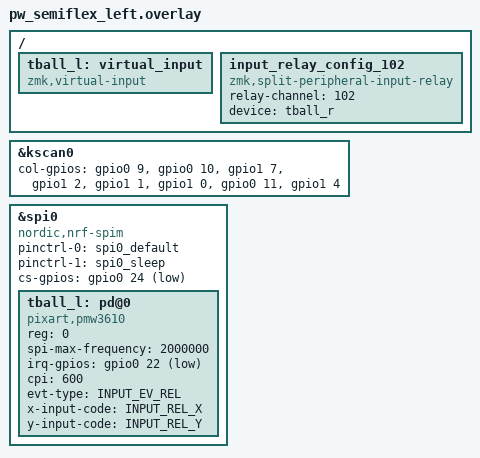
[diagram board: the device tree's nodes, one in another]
#include "pw_semiflex.dtsi"

#define INPUT_EV_KEY 0x01               /**< Key event */
#define INPUT_EV_REL 0x02               /**< Relative coordinate event */
#define INPUT_EV_ABS 0x03               /**< Absolute coordinate event */
#define INPUT_EV_MSC 0x04               /**< Miscellaneous event */
#define INPUT_EV_VENDOR_START 0xf0      /**< Vendor specific event start */
#define INPUT_EV_VENDOR_STOP 0xff       /**< Vendor specific event stop */

#define INPUT_REL_X 0x00                /**< Relative X coordinate */
#define INPUT_REL_Y 0x01                /**< Relative Y coordinate */
#define INPUT_REL_WHEEL 0x08            /**< Relative wheel coordinate */
#define INPUT_REL_HWHEEL 0x06           /**< Relative horizontal wheel coordinate */
#define INPUT_REL_MISC 0x09             /**< Relative misc coordinate */

// Left is main

&kscan0 {
    col-gpios
        = <&gpio0 9 GPIO_ACTIVE_HIGH> // Column 1
        , <&gpio0 10 GPIO_ACTIVE_HIGH> // Column 2
        , <&gpio1 7 GPIO_ACTIVE_HIGH> // Column 3
        , <&gpio1 2 GPIO_ACTIVE_HIGH> // Column 4
        , <&gpio1 1 GPIO_ACTIVE_HIGH> // Column 5
        , <&gpio1 0 GPIO_ACTIVE_HIGH> // Column 6
        , <&gpio0 11 GPIO_ACTIVE_HIGH> // Column 7
        , <&gpio1 4 GPIO_ACTIVE_HIGH> // Column 8
        ;
};

&spi0 {
    status = "okay";
    compatible = "nordic,nrf-spim";
    pinctrl-0 = <&spi0_default>;
    pinctrl-1 = <&spi0_sleep>;
    pinctrl-names = "default", "sleep";
    cs-gpios = <&gpio0 24 GPIO_ACTIVE_LOW>;

    tball_l: pd@0 {
        status = "okay";
        compatible = "pixart,pmw3610";
        reg = <0>;
        spi-max-frequency = <2000000>;
        irq-gpios = <&gpio0 22 (GPIO_ACTIVE_LOW | GPIO_PULL_UP)>;
        cpi = <600>;
        evt-type = <INPUT_EV_REL>;
        x-input-code = <INPUT_REL_X>;
        y-input-code = <INPUT_REL_Y>;
        /*   optional features   */
        // snipe-layers = <1>;
        // scroll-layers = <2>;
        // automouse-layer = <4>;
    };
};

/ {
	/* define virtual input, will be resurrected for emitting input event */
	/* NOTE: set `device = <&pd1>` in `zmk,input-listener` */
	tball_l: virtual_input {
		compatible = "zmk,virtual-input";
	};

	/* for central side, define (relay-channel)-to-(virtual-input) mapping */
	input_relay_config_102 {
		compatible = "zmk,split-peripheral-input-relay";
		
		/* channel id, used to filter incoming input event from split peripheral */
		/* NOTE: should matching relay-channel on peripheral overlay */
		relay-channel = <102>;

		/* virtual input device on central, which used to emit input event as an agent device */
		device = <&tball_r>;
	};
};
